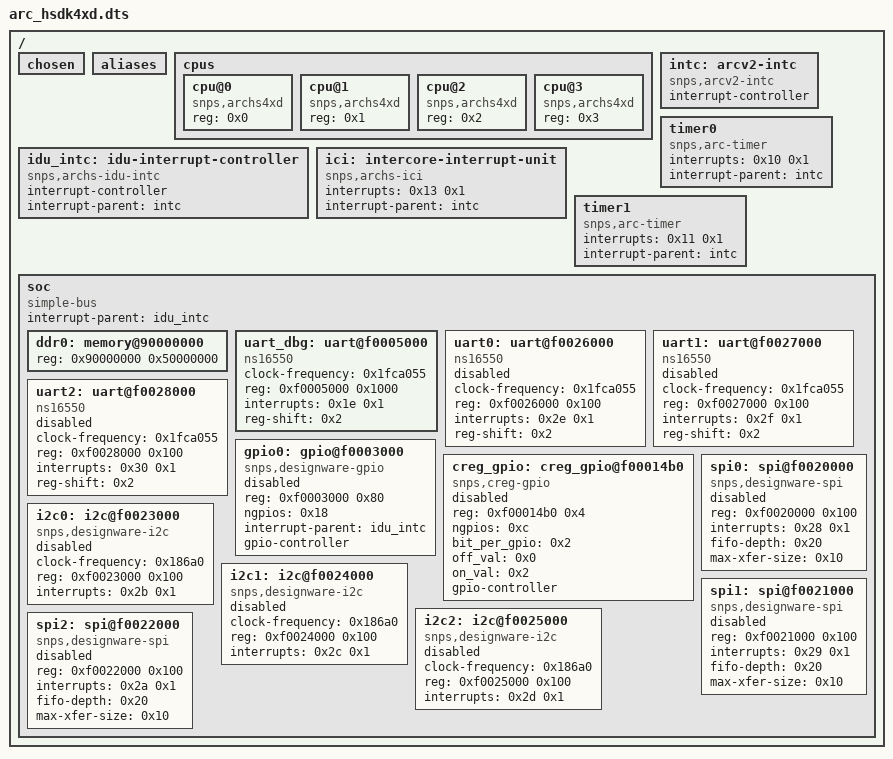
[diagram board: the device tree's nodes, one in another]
/dts-v1/;

/ {
	#address-cells = < 0x1 >;
	#size-cells = < 0x1 >;
	chosen {
	};
	aliases {
	};
	cpus {
		#address-cells = < 0x1 >;
		#size-cells = < 0x0 >;
		cpu@0 {
			device_type = "cpu";
			compatible = "snps,archs4xd";
			reg = < 0x0 >;
		};
		cpu@1 {
			device_type = "cpu";
			compatible = "snps,archs4xd";
			reg = < 0x1 >;
		};
		cpu@2 {
			device_type = "cpu";
			compatible = "snps,archs4xd";
			reg = < 0x2 >;
		};
		cpu@3 {
			device_type = "cpu";
			compatible = "snps,archs4xd";
			reg = < 0x3 >;
		};
	};
	intc: arcv2-intc {
		compatible = "snps,arcv2-intc";
		interrupt-controller;
		#interrupt-cells = < 0x2 >;
		phandle = < 0x1 >;
	};
	idu_intc: idu-interrupt-controller {
		compatible = "snps,archs-idu-intc";
		interrupt-controller;
		#interrupt-cells = < 0x2 >;
		interrupt-parent = < &intc >;
		phandle = < 0x2 >;
	};
	ici: intercore-interrupt-unit {
		compatible = "snps,archs-ici";
		interrupts = < 0x13 0x1 >;
		interrupt-parent = < &intc >;
	};
	timer0: timer0 {
		compatible = "snps,arc-timer";
		interrupts = < 0x10 0x1 >;
		interrupt-parent = < &intc >;
	};
	timer1: timer1 {
		compatible = "snps,arc-timer";
		interrupts = < 0x11 0x1 >;
		interrupt-parent = < &intc >;
	};
	soc {
		#address-cells = < 0x1 >;
		#size-cells = < 0x1 >;
		compatible = "simple-bus";
		interrupt-parent = < &idu_intc >;
		ranges;
		ddr0: memory@90000000 {
			device_type = "memory";
			reg = < 0x90000000 0x50000000 >;
		};
		uart_dbg: uart@f0005000 {
			compatible = "ns16550";
			clock-frequency = < 0x1fca055 >;
			reg = < 0xf0005000 0x1000 >;
			interrupts = < 0x1e 0x1 >;
			reg-shift = < 0x2 >;
		};
		uart0: uart@f0026000 {
			compatible = "ns16550";
			clock-frequency = < 0x1fca055 >;
			reg = < 0xf0026000 0x100 >;
			interrupts = < 0x2e 0x1 >;
			reg-shift = < 0x2 >;
			status = "disabled";
		};
		uart1: uart@f0027000 {
			compatible = "ns16550";
			clock-frequency = < 0x1fca055 >;
			reg = < 0xf0027000 0x100 >;
			interrupts = < 0x2f 0x1 >;
			reg-shift = < 0x2 >;
			status = "disabled";
		};
		uart2: uart@f0028000 {
			compatible = "ns16550";
			clock-frequency = < 0x1fca055 >;
			reg = < 0xf0028000 0x100 >;
			interrupts = < 0x30 0x1 >;
			reg-shift = < 0x2 >;
			status = "disabled";
		};
		gpio0: gpio@f0003000 {
			compatible = "snps,designware-gpio";
			reg = < 0xf0003000 0x80 >;
			ngpios = < 0x18 >;
			interrupt-parent = < &idu_intc >;
			gpio-controller;
			#gpio-cells = < 0x2 >;
			status = "disabled";
		};
		creg_gpio: creg_gpio@f00014b0 {
			compatible = "snps,creg-gpio";
			reg = < 0xf00014b0 0x4 >;
			ngpios = < 0xc >;
			bit_per_gpio = < 0x2 >;
			off_val = < 0x0 >;
			on_val = < 0x2 >;
			gpio-controller;
			#gpio-cells = < 0x2 >;
			status = "disabled";
		};
		i2c0: i2c@f0023000 {
			compatible = "snps,designware-i2c";
			clock-frequency = < 0x186a0 >;
			#address-cells = < 0x1 >;
			#size-cells = < 0x0 >;
			reg = < 0xf0023000 0x100 >;
			interrupts = < 0x2b 0x1 >;
			status = "disabled";
		};
		i2c1: i2c@f0024000 {
			compatible = "snps,designware-i2c";
			clock-frequency = < 0x186a0 >;
			#address-cells = < 0x1 >;
			#size-cells = < 0x0 >;
			reg = < 0xf0024000 0x100 >;
			interrupts = < 0x2c 0x1 >;
			status = "disabled";
		};
		i2c2: i2c@f0025000 {
			compatible = "snps,designware-i2c";
			clock-frequency = < 0x186a0 >;
			#address-cells = < 0x1 >;
			#size-cells = < 0x0 >;
			reg = < 0xf0025000 0x100 >;
			interrupts = < 0x2d 0x1 >;
			status = "disabled";
		};
		spi0: spi@f0020000 {
			compatible = "snps,designware-spi";
			#address-cells = < 0x1 >;
			#size-cells = < 0x0 >;
			reg = < 0xf0020000 0x100 >;
			interrupts = < 0x28 0x1 >;
			fifo-depth = < 0x20 >;
			max-xfer-size = < 0x10 >;
			status = "disabled";
		};
		spi1: spi@f0021000 {
			compatible = "snps,designware-spi";
			#address-cells = < 0x1 >;
			#size-cells = < 0x0 >;
			reg = < 0xf0021000 0x100 >;
			interrupts = < 0x29 0x1 >;
			fifo-depth = < 0x20 >;
			max-xfer-size = < 0x10 >;
			status = "disabled";
		};
		spi2: spi@f0022000 {
			compatible = "snps,designware-spi";
			#address-cells = < 0x1 >;
			#size-cells = < 0x0 >;
			reg = < 0xf0022000 0x100 >;
			interrupts = < 0x2a 0x1 >;
			fifo-depth = < 0x20 >;
			max-xfer-size = < 0x10 >;
			status = "disabled";
		};
	};
};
